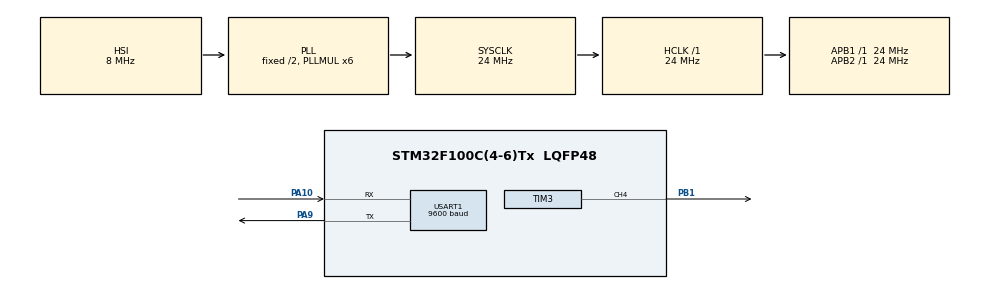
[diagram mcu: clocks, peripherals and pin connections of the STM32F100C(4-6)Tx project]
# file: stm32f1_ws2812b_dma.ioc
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Dma.Request0=TIM3_CH4/UP
Dma.TIM3_CH4/UP.0.Direction=DMA_MEMORY_TO_PERIPH
Dma.TIM3_CH4/UP.0.Instance=DMA1_Channel3
Dma.TIM3_CH4/UP.0.MemDataAlignment=DMA_MDATAALIGN_BYTE
Dma.TIM3_CH4/UP.0.MemInc=DMA_MINC_ENABLE
Dma.TIM3_CH4/UP.0.Mode=DMA_CIRCULAR
Dma.TIM3_CH4/UP.0.PeriphDataAlignment=DMA_PDATAALIGN_HALFWORD
Dma.TIM3_CH4/UP.0.PeriphInc=DMA_PINC_DISABLE
Dma.TIM3_CH4/UP.0.Priority=DMA_PRIORITY_HIGH
Mcu.Family=STM32F1
Mcu.Name=STM32F100C(4-6)Tx
Mcu.Package=LQFP48
NVIC.DMA1_Channel3_IRQn=true\:0\:0\:false\:false\:true
NVIC.PriorityGroup=NVIC_PRIORITYGROUP_4
NVIC.USART1_IRQn=true\:0\:0\:false\:false\:true
PA10.Mode=Asynchronous
PA10.Signal=USART1_RX
PA9.Mode=Asynchronous
PA9.Signal=USART1_TX
PB1.GPIO_Speed=GPIO_SPEED_FREQ_HIGH
PB1.Signal=S_TIM3_CH4
ProjectManager.HeapSize=0x200
ProjectManager.StackSize=0x400
ProjectManager.TargetToolchain=MDK-ARM V5
RCC.AHBFreq_Value=24000000
RCC.APB1Freq_Value=24000000
RCC.APB1TimFreq_Value=24000000
RCC.APB2Freq_Value=24000000
RCC.APB2TimFreq_Value=24000000
RCC.HCLKFreq_Value=24000000
RCC.PLLMUL=RCC_PLL_MUL6
RCC.SYSCLKFreq_VALUE=24000000
RCC.SYSCLKSource=RCC_SYSCLKSOURCE_PLLCLK
RCC.VDD_VALUE=3.3
SH.S_TIM3_CH4.0=TIM3_CH4,PWM Generation4 CH4
TIM3.Channel-PWM\ Generation4\ CH4=TIM_CHANNEL_4
TIM3.Period=29
TIM3.Prescaler=0
USART1.BaudRate=9600
VP_SYS_VS_ND.Mode=No_Debug
VP_TIM3_VS_ClockSourceINT.Mode=Internal
board=stm32f1_ws2812b_dma

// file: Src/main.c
/**
  ******************************************************************************
  * File Name          : main.c
  * Description        : Main program body
  ******************************************************************************
  *
  * COPYRIGHT(c) 2016 STMicroelectronics
  *
  * Redistribution and use in source and binary forms, with or without modification,
  * are permitted provided that the following conditions are met:
  *   1. Redistributions of source code must retain the above copyright notice,
  *      this list of conditions and the following disclaimer.
  *   2. Redistributions in binary form must reproduce the above copyright notice,
  *      this list of conditions and the following disclaimer in the documentation
  *      and/or other materials provided with the distribution.
  *   3. Neither the name of STMicroelectronics nor the names of its contributors
  *      may be used to endorse or promote products derived from this software
  *      without specific prior written permission.
  *
  * THIS SOFTWARE IS PROVIDED BY THE COPYRIGHT HOLDERS AND CONTRIBUTORS "AS IS"
  * AND ANY EXPRESS OR IMPLIED WARRANTIES, INCLUDING, BUT NOT LIMITED TO, THE
  * IMPLIED WARRANTIES OF MERCHANTABILITY AND FITNESS FOR A PARTICULAR PURPOSE ARE
  * DISCLAIMED. IN NO EVENT SHALL THE COPYRIGHT HOLDER OR CONTRIBUTORS BE LIABLE
  * FOR ANY DIRECT, INDIRECT, INCIDENTAL, SPECIAL, EXEMPLARY, OR CONSEQUENTIAL
  * DAMAGES (INCLUDING, BUT NOT LIMITED TO, PROCUREMENT OF SUBSTITUTE GOODS OR
  * SERVICES; LOSS OF USE, DATA, OR PROFITS; OR BUSINESS INTERRUPTION) HOWEVER
  * CAUSED AND ON ANY THEORY OF LIABILITY, WHETHER IN CONTRACT, STRICT LIABILITY,
  * OR TORT (INCLUDING NEGLIGENCE OR OTHERWISE) ARISING IN ANY WAY OUT OF THE USE
  * OF THIS SOFTWARE, EVEN IF ADVISED OF THE POSSIBILITY OF SUCH DAMAGE.
  *
  ******************************************************************************
  */
#include "main.h"
#include "stm32f1xx_hal.h"

/* USER CODE BEGIN Includes */
#include "ws2812b.h"
/* USER CODE END Includes */

TIM_HandleTypeDef htim3;
DMA_HandleTypeDef hdma_tim3_ch4_up;

UART_HandleTypeDef huart1;

/* USER CODE BEGIN PV */
/* Private variables ---------------------------------------------------------*/

/* USER CODE END PV */

void SystemClock_Config(void);
void Error_Handler(void);
static void MX_GPIO_Init(void);
static void MX_DMA_Init(void);
static void MX_TIM3_Init(void);
static void MX_USART1_UART_Init(void);
void HAL_TIM_MspPostInit(TIM_HandleTypeDef *htim);

/* USER CODE BEGIN PFP */
/* Private function prototypes -----------------------------------------------*/

/* USER CODE END PFP */

/* USER CODE BEGIN 0 */
uint8_t aRxBuffer[6];

const uint8_t ledsNumber = 4;
const uint8_t preambleSize = 2;
LedColor leds[ledsNumber];
PwmColor pwmColor[preambleSize + ledsNumber];

uint16_t bufferSize = (preambleSize + ledsNumber) * 3 * 8;

void SetLedColor(LedColor * leds, PwmColor *pwmColor, uint16_t index, LedColor *color)
{
    leds[index].Red = color->Red;
    leds[index].Green = color->Green;
    leds[index].Blue = color->Blue;

    ConvertColorLedToPwm(&leds[index], &pwmColor[preambleSize + index]);
}

void SetAllLedColor(LedColor * leds, PwmColor *pwmColor, LedColor *color)
{
    for(int i = 0; i < ledsNumber; i++)
    {
        SetLedColor(leds, pwmColor, i, color);
    }
}

void ClearAllLeds(LedColor * leds, PwmColor *pwmColor)
{
    for(int i = 0; i < ledsNumber; i++)
    {
        ClearLedColor(&leds[i]);
    }

    for(int i = 0; i < preambleSize + ledsNumber; i++)
    {
        ClearPwmColor(&pwmColor[i]);
    }
}

void ConvertAllLedsToPwm(LedColor * leds, PwmColor *pwmColor)
{
    for(int i = 0; i < ledsNumber; i++)
    {
        ConvertColorLedToPwm(&leds[i], &pwmColor[preambleSize + i]);
    }
}

void MoveLeds(LedColor * leds, PwmColor *pwmColor)
{
    LedColor temp = leds[ledsNumber - 1];

    for(int i=ledsNumber - 1; i > 0; i--)
    {
        leds[i] = leds[i - 1];
    }
    leds[0] = temp;
}
/* USER CODE END 0 */

int main(void)
{

  /* MCU Configuration----------------------------------------------------------*/

  /* Reset of all peripherals, Initializes the Flash interface and the Systick. */
  HAL_Init();

  /* Configure the system clock */
  SystemClock_Config();

  /* Initialize all configured peripherals */
  MX_GPIO_Init();
  MX_DMA_Init();
  MX_TIM3_Init();
  MX_USART1_UART_Init();

  /* USER CODE BEGIN 2 */
	//HAL_TIM_Base_Start_IT(&htim6);
	//HAL_TIM_PWM_Start(&htim3, TIM_CHANNEL_4);
	//TIM3->CCR4 = 20;
    ClearAllLeds(leds, pwmColor);
    uint8_t light = 2;

    LedColor greenColor = { .Red = 0, .Green = light, .Blue = 0};
    LedColor redColor = { .Red = light, .Green = 0, .Blue = 0};
    LedColor blueColor = { .Red = 0, .Green = 0, .Blue = light};
    LedColor yellowColor = { .Red = light, .Green = light, .Blue = 0};

    //for(int i=0; i<ledsNumber; i++)
    //{
    //    if (i%9 == 0)
    //    {
    //        SetLedColor(leds, pwmColor, i, &greenColor);
    //    }
    //    else if (i%6 == 0)
    //    {
    //        SetLedColor(leds, pwmColor, i, &blueColor);
    //    }
    //    else if (i%3 == 0)
    //    {
    //        SetLedColor(leds, pwmColor, i, &redColor);
    //    }
    //    else
    //    {
    //        SetLedColor(leds, pwmColor, i, &yellowColor);
    //    }
    //}

    SetLedColor(leds, pwmColor, 0, &greenColor);
    SetLedColor(leds, pwmColor, 1, &redColor);
    SetLedColor(leds, pwmColor, 2, &blueColor);
    SetLedColor(leds, pwmColor, 3, &yellowColor);

    //HAL_UART_Transmit(&huart1, (uint8_t *)"hello\r\n", 7, 5000);
    HAL_UART_Transmit_IT(&huart1, (uint8_t *)"hello\r\n", 7);
    HAL_UART_Receive_IT(&huart1, aRxBuffer, 3);

	//HAL_Delay(1000);
	//HAL_TIM_PWM_Start_DMA(&htim3, TIM_CHANNEL_4, (uint32_t *)pwmColor, bufferSize);
  /* USER CODE END 2 */

  /* Infinite loop */
  /* USER CODE BEGIN WHILE */
    while (1)
    {
        //redColor.Red = light + 1;
        //SetLedColor(leds, pwmColor, 0, &redColor);
        //HAL_TIM_PWM_Start_DMA(&htim3, TIM_CHANNEL_4, (uint32_t *)pwmColor, bufferSize);
        //light++;
        //
        //if (light == 255)
        //{
        //    light = 0;
        //}
        //HAL_Delay(125);
        MoveLeds(leds, pwmColor);
        ConvertAllLedsToPwm(leds, pwmColor);
        HAL_TIM_PWM_Start_DMA(&htim3, TIM_CHANNEL_4, (uint32_t *)pwmColor, bufferSize);
        HAL_Delay(250);

  /* USER CODE END WHILE */

    }

}

/** System Clock Configuration
*/
void SystemClock_Config(void)
{

  RCC_OscInitTypeDef RCC_OscInitStruct;
  RCC_ClkInitTypeDef RCC_ClkInitStruct;

    /**Initializes the CPU, AHB and APB busses clocks
    */
  RCC_OscInitStruct.OscillatorType = RCC_OSCILLATORTYPE_HSI;
  RCC_OscInitStruct.HSIState = RCC_HSI_ON;
  RCC_OscInitStruct.HSICalibrationValue = 16;
  RCC_OscInitStruct.PLL.PLLState = RCC_PLL_ON;
  RCC_OscInitStruct.PLL.PLLSource = RCC_PLLSOURCE_HSI_DIV2;
  RCC_OscInitStruct.PLL.PLLMUL = RCC_PLL_MUL6;
  if (HAL_RCC_OscConfig(&RCC_OscInitStruct) != HAL_OK)
  {
    Error_Handler();
  }

    /**Initializes the CPU, AHB and APB busses clocks
    */
  RCC_ClkInitStruct.ClockType = RCC_CLOCKTYPE_HCLK|RCC_CLOCKTYPE_SYSCLK
                              |RCC_CLOCKTYPE_PCLK1|RCC_CLOCKTYPE_PCLK2;
  RCC_ClkInitStruct.SYSCLKSource = RCC_SYSCLKSOURCE_PLLCLK;
  RCC_ClkInitStruct.AHBCLKDivider = RCC_SYSCLK_DIV1;
  RCC_ClkInitStruct.APB1CLKDivider = RCC_HCLK_DIV1;
  RCC_ClkInitStruct.APB2CLKDivider = RCC_HCLK_DIV1;

  if (HAL_RCC_ClockConfig(&RCC_ClkInitStruct, FLASH_LATENCY_0) != HAL_OK)
  {
    Error_Handler();
  }

    /**Configure the Systick interrupt time
    */
  HAL_SYSTICK_Config(HAL_RCC_GetHCLKFreq()/1000);

    /**Configure the Systick
    */
  HAL_SYSTICK_CLKSourceConfig(SYSTICK_CLKSOURCE_HCLK);

  /* SysTick_IRQn interrupt configuration */
  HAL_NVIC_SetPriority(SysTick_IRQn, 0, 0);
}

/* TIM3 init function */
static void MX_TIM3_Init(void)
{

  TIM_ClockConfigTypeDef sClockSourceConfig;
  TIM_MasterConfigTypeDef sMasterConfig;
  TIM_OC_InitTypeDef sConfigOC;

  htim3.Instance = TIM3;
  htim3.Init.Prescaler = 0;
  htim3.Init.CounterMode = TIM_COUNTERMODE_UP;
  htim3.Init.Period = 29;
  htim3.Init.ClockDivision = TIM_CLOCKDIVISION_DIV1;
  if (HAL_TIM_Base_Init(&htim3) != HAL_OK)
  {
    Error_Handler();
  }

  sClockSourceConfig.ClockSource = TIM_CLOCKSOURCE_INTERNAL;
  if (HAL_TIM_ConfigClockSource(&htim3, &sClockSourceConfig) != HAL_OK)
  {
    Error_Handler();
  }

  if (HAL_TIM_PWM_Init(&htim3) != HAL_OK)
  {
    Error_Handler();
  }

  sMasterConfig.MasterOutputTrigger = TIM_TRGO_RESET;
  sMasterConfig.MasterSlaveMode = TIM_MASTERSLAVEMODE_DISABLE;
  if (HAL_TIMEx_MasterConfigSynchronization(&htim3, &sMasterConfig) != HAL_OK)
  {
    Error_Handler();
  }

  sConfigOC.OCMode = TIM_OCMODE_PWM1;
  sConfigOC.Pulse = 0;
  sConfigOC.OCPolarity = TIM_OCPOLARITY_HIGH;
  sConfigOC.OCFastMode = TIM_OCFAST_DISABLE;
  if (HAL_TIM_PWM_ConfigChannel(&htim3, &sConfigOC, TIM_CHANNEL_4) != HAL_OK)
  {
    Error_Handler();
  }

  HAL_TIM_MspPostInit(&htim3);

}

/* USART1 init function */
static void MX_USART1_UART_Init(void)
{

  huart1.Instance = USART1;
  huart1.Init.BaudRate = 9600;
  huart1.Init.WordLength = UART_WORDLENGTH_8B;
  huart1.Init.StopBits = UART_STOPBITS_1;
  huart1.Init.Parity = UART_PARITY_NONE;
  huart1.Init.Mode = UART_MODE_TX_RX;
  huart1.Init.HwFlowCtl = UART_HWCONTROL_NONE;
  huart1.Init.OverSampling = UART_OVERSAMPLING_16;
  if (HAL_UART_Init(&huart1) != HAL_OK)
  {
    Error_Handler();
  }

}

static void MX_DMA_Init(void)
{
  /* DMA controller clock enable */
  __HAL_RCC_DMA1_CLK_ENABLE();

  /* DMA interrupt init */
  /* DMA1_Channel3_IRQn interrupt configuration */
  HAL_NVIC_SetPriority(DMA1_Channel3_IRQn, 0, 0);
  HAL_NVIC_EnableIRQ(DMA1_Channel3_IRQn);

}

/** Pinout Configuration
*/
static void MX_GPIO_Init(void)
{

  /* GPIO Ports Clock Enable */
  __HAL_RCC_GPIOB_CLK_ENABLE();
  __HAL_RCC_GPIOA_CLK_ENABLE();

}

/* USER CODE BEGIN 4 */

//void HAL_TIM_PeriodElapsedCallback(TIM_HandleTypeDef *htim)
//{
//	HAL_GPIO_TogglePin(GPIOA, GPIO_PIN_11);
//}

void HAL_TIM_PWM_PulseFinishedCallback(TIM_HandleTypeDef *htim)
{
	HAL_TIM_PWM_Stop_DMA(&htim3, TIM_CHANNEL_4);
}

void HAL_UART_RxCpltCallback(UART_HandleTypeDef *huart)
{
    LedColor receivedColor = { .Red = aRxBuffer[0], .Green = aRxBuffer[1], .Blue = aRxBuffer[2]};
    SetAllLedColor(leds, pwmColor, &receivedColor);
    HAL_UART_Transmit_IT(&huart1, aRxBuffer, 3);
    HAL_UART_Receive_IT(&huart1, aRxBuffer, 3);
}
/* USER CODE END 4 */

void Error_Handler(void)
{
  while(1)
  {
  }
}

/************************ (C) COPYRIGHT STMicroelectronics *****END OF FILE****/
